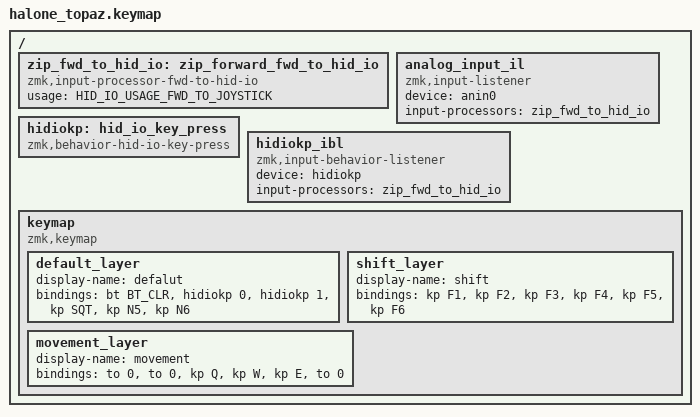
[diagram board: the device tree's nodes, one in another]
#include <behaviors.dtsi>
#include <dt-bindings/zmk/keys.h>
#include <dt-bindings/zmk/bt.h>

// index of keymap layers
#define DEF 0 // default layer

#define HID_IO_USAGE_FWD_TO_MOUSE 1
#define HID_IO_USAGE_FWD_TO_JOYSTICK 2
#define ZIP_HID_IO_USAGE_FWD_TO_VOLUME_KNOB 3

/ {
    /* Setup input-processor to intecept input and forward to new usage page  */
    zip_fwd_to_hid_io: zip_forward_fwd_to_hid_io {
        compatible = "zmk,input-processor-fwd-to-hid-io";
        #input-processor-cells = <0>;
        usage = <HID_IO_USAGE_FWD_TO_JOYSTICK>;
    };

    /* input listener config for mouse move mode */
	analog_input_il {
		compatible = "zmk,input-listener";
		device = <&anin0>;
        input-processors = <&zip_fwd_to_hid_io>;
	};

    /* Setup joystick key press behavior and listener */
    /* listerer shall forward to JOYSTICK usage page if CONFIG_ZMK_HID_IO_JOYSTICK enabling */
    hidiokp: hid_io_key_press {
        compatible = "zmk,behavior-hid-io-key-press";
        #binding-cells = <1>;
    };
	hidiokp_ibl {
		compatible = "zmk,input-behavior-listener";
		device = <&hidiokp>;
        input-processors = <&zip_fwd_to_hid_io>;
	};

    keymap {
        compatible = "zmk,keymap";
        
        default_layer {
            display-name = "defalut";

            bindings = <
                &bt BT_CLR      &hidiokp 0      &hidiokp 1      &kp SQT         &kp N5          &kp N6
            >;
        };

        shift_layer {
            display-name = "shift";

            bindings = <
                &kp F1          &kp F2          &kp F3          &kp F4          &kp F5          &kp F6
            >;
        };

        movement_layer {
            display-name = "movement";

            bindings = <
                &to 0           &to 0           &kp Q           &kp W           &kp E           &to 0
            >;
        };
    };
};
